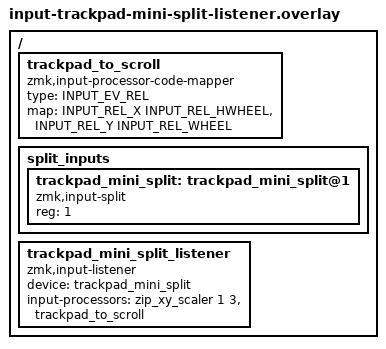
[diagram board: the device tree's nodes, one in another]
#include <dt-bindings/input/input-event-codes.h>
#include <input/processors.dtsi>

/{
    /* X/Y 移動をスクロールに変換 */
    trackpad_to_scroll: trackpad_to_scroll {
        compatible = "zmk,input-processor-code-mapper";
        #input-processor-cells = <0>;
        type = <INPUT_EV_REL>;
        map = <INPUT_REL_X INPUT_REL_HWHEEL>
            , <INPUT_REL_Y INPUT_REL_WHEEL>;
    };

    split_inputs {
        #address-cells = <1>;
        #size-cells = <0>;

        trackpad_mini_split: trackpad_mini_split@1 {
            compatible = "zmk,input-split";
            reg = <1>;
        };
    };

    trackpad_mini_split_listener: trackpad_mini_split_listener {
        compatible = "zmk,input-listener";
        device = <&trackpad_mini_split>;
        status = "okay";
        input-processors = <&zip_xy_scaler 1 3 &trackpad_to_scroll>;
    };
};
